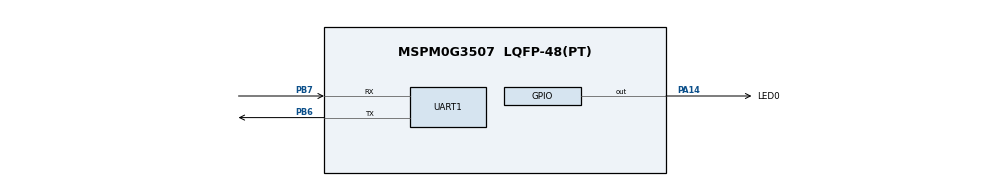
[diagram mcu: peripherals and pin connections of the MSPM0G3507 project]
//@cliArgs --device "MSPM0G350X" --package "LQFP-48(PT)" --part "Default"
//@v2CliArgs --device "MSPM0G3507" --package "LQFP-48(PT)"

/**
 * Import the modules used in this configuration.
 */
const UART    = scripting.addModule("/ti/driverlib/UART", {}, false);
const UART1   = UART.addInstance();
const GPIO    = scripting.addModule("/ti/driverlib/GPIO", {}, false);
const GPIO1   = GPIO.addInstance();
const SYSCTL  = scripting.addModule("/ti/driverlib/SYSCTL");

/**
 * Write custom configuration values to the imported modules.
 */
UART1.$name                    = "UART_DEBUG";
UART1.enableFIFO               = true;
UART1.targetBaudRate           = 115200;
UART1.enableMajorityVoting     = true;
UART1.peripheral.$assign       = "UART1";
UART1.peripheral.rxPin.$assign = "PB7";
UART1.peripheral.txPin.$assign = "PB6";

GPIO1.$name                         = "LED";
GPIO1.associatedPins.create(1);
GPIO1.associatedPins[0].$name       = "LED0";
GPIO1.associatedPins[0].pin.$assign = "PA14";

const Board = scripting.addModule("/ti/driverlib/Board", {}, false);

SYSCTL.forceDefaultClkConfig = true;
